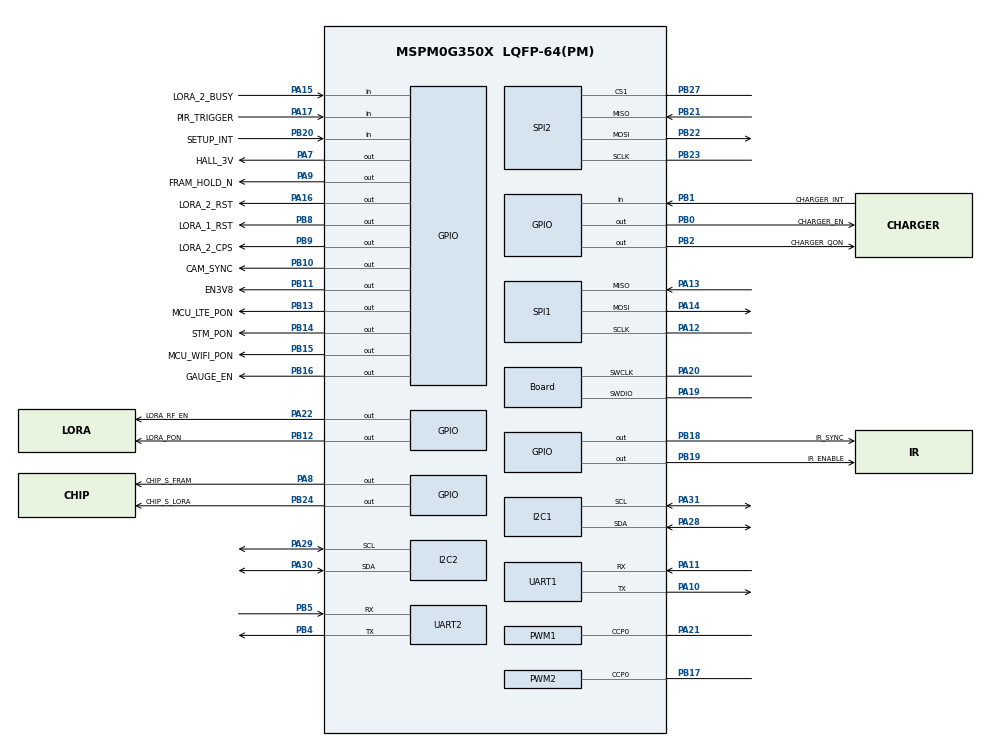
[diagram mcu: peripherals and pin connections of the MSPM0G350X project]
/**
 * @cliArgs --device "MSPM0G350X" --part "Default" --package "LQFP-64(PM)" --product "mspm0_sdk@2.09.00.01"
 * @versions {"tool":"1.25.0+4268"}
 */

/**
 * Import the modules used in this configuration.
 */
const Board  = scripting.addModule("/ti/driverlib/Board");
const GPIO   = scripting.addModule("/ti/driverlib/GPIO", {}, false);
const GPIO1  = GPIO.addInstance();
const GPIO2  = GPIO.addInstance();
const GPIO3  = GPIO.addInstance();
const I2C    = scripting.addModule("/ti/driverlib/I2C", {}, false);
const I2C1   = I2C.addInstance();
const I2C2   = I2C.addInstance();
const PWM    = scripting.addModule("/ti/driverlib/PWM", {}, false);
const PWM1   = PWM.addInstance();
const PWM2   = PWM.addInstance();
const SPI    = scripting.addModule("/ti/driverlib/SPI", {}, false);
const SPI1   = SPI.addInstance();
const SPI2   = SPI.addInstance();
const SYSCTL = scripting.addModule("/ti/driverlib/SYSCTL");
const TIMER  = scripting.addModule("/ti/driverlib/TIMER", {}, false);
const TIMER1 = TIMER.addInstance();
const UART   = scripting.addModule("/ti/driverlib/UART", {}, false);
const UART1  = UART.addInstance();
const UART2  = UART.addInstance();

/**
 * Write custom configuration values to the imported modules.
 */
Board.peripheral.swclkPin.$assign = "PA20";
Board.peripheral.swdioPin.$assign = "PA19";

GPIO1.$name                                 = "EXTERNAL_INTERRUPT";
GPIO1.associatedPins.create(4);
GPIO1.associatedPins[0].$name               = "PIR_TRIGGER";
GPIO1.associatedPins[0].direction           = "INPUT";
GPIO1.associatedPins[0].ioStructure         = "SDW";
GPIO1.associatedPins[0].assignedPin         = "17";
GPIO1.associatedPins[0].assignedPort        = "PORTA";
GPIO1.associatedPins[0].assignedPortSegment = "Upper";
GPIO1.associatedPins[0].pin.$assign         = "PA17";
GPIO1.associatedPins[1].$name               = "CHARGER_INT";
GPIO1.associatedPins[1].direction           = "INPUT";
GPIO1.associatedPins[1].assignedPin         = "any";
GPIO1.associatedPins[1].ioStructure         = "SD";
GPIO1.associatedPins[1].interruptEn         = true;
GPIO1.associatedPins[1].polarity            = "RISE_FALL";
GPIO1.associatedPins[1].pin.$assign         = "PB1";
GPIO1.associatedPins[2].$name               = "LORA_2_BUSY";
GPIO1.associatedPins[2].direction           = "INPUT";
GPIO1.associatedPins[2].ioStructure         = "SD";
GPIO1.associatedPins[2].pin.$assign         = "PA15";
GPIO1.associatedPins[3].$name               = "SETUP_INT";
GPIO1.associatedPins[3].direction           = "INPUT";
GPIO1.associatedPins[3].assignedPort        = "PORTB";
GPIO1.associatedPins[3].assignedPin         = "any";
GPIO1.associatedPins[3].pin.$assign         = "PB20";

GPIO2.$name                          = "DIGITAL_OUTPUT_PORTB";
GPIO2.port                           = "PORTB";
GPIO2.associatedPins.create(14);
GPIO2.associatedPins[0].$name        = "CHARGER_EN";
GPIO2.associatedPins[0].ioStructure  = "SD";
GPIO2.associatedPins[0].assignedPin  = "0";
GPIO2.associatedPins[0].initialValue = "SET";
GPIO2.associatedPins[0].pin.$assign  = "PB0";
GPIO2.associatedPins[1].$name        = "CHARGER_QON";
GPIO2.associatedPins[1].ioStructure  = "SD";
GPIO2.associatedPins[1].assignedPin  = "2";
GPIO2.associatedPins[1].initialValue = "SET";
GPIO2.associatedPins[1].pin.$assign  = "PB2";
GPIO2.associatedPins[2].$name        = "LORA_1_RST";
GPIO2.associatedPins[2].ioStructure  = "SD";
GPIO2.associatedPins[2].assignedPin  = "8";
GPIO2.associatedPins[2].pin.$assign  = "PB8";
GPIO2.associatedPins[3].assignedPin  = "11";
GPIO2.associatedPins[3].ioStructure  = "SD";
GPIO2.associatedPins[3].$name        = "EN3V8";
GPIO2.associatedPins[3].pin.$assign  = "PB11";
GPIO2.associatedPins[4].$name        = "LORA_PON";
GPIO2.associatedPins[4].ioStructure  = "SD";
GPIO2.associatedPins[4].assignedPin  = "12";
GPIO2.associatedPins[4].pin.$assign  = "PB12";
GPIO2.associatedPins[5].$name        = "MCU_LTE_PON";
GPIO2.associatedPins[5].ioStructure  = "SD";
GPIO2.associatedPins[5].assignedPin  = "13";
GPIO2.associatedPins[5].pin.$assign  = "PB13";
GPIO2.associatedPins[6].$name        = "STM_PON";
GPIO2.associatedPins[6].ioStructure  = "SD";
GPIO2.associatedPins[6].assignedPin  = "14";
GPIO2.associatedPins[6].pin.$assign  = "PB14";
GPIO2.associatedPins[7].ioStructure  = "SD";
GPIO2.associatedPins[7].assignedPin  = "15";
GPIO2.associatedPins[7].$name        = "MCU_WIFI_PON";
GPIO2.associatedPins[7].pin.$assign  = "PB15";
GPIO2.associatedPins[8].assignedPin  = "18";
GPIO2.associatedPins[8].ioStructure  = "SD";
GPIO2.associatedPins[8].$name        = "IR_SYNC";
GPIO2.associatedPins[8].pin.$assign  = "PB18";
GPIO2.associatedPins[9].$name        = "IR_ENABLE";
GPIO2.associatedPins[9].ioStructure  = "SD";
GPIO2.associatedPins[9].assignedPin  = "19";
GPIO2.associatedPins[9].pin.$assign  = "PB19";
GPIO2.associatedPins[10].$name       = "CAM_SYNC";
GPIO2.associatedPins[10].ioStructure = "SD";
GPIO2.associatedPins[10].assignedPin = "10";
GPIO2.associatedPins[10].pin.$assign = "PB10";
GPIO2.associatedPins[11].$name       = "GAUGE_EN";
GPIO2.associatedPins[11].pin.$assign = "PB16";
GPIO2.associatedPins[12].$name       = "LORA_2_CPS";
GPIO2.associatedPins[12].pin.$assign = "PB9";
GPIO2.associatedPins[13].$name       = "CHIP_S_LORA";
GPIO2.associatedPins[13].pin.$assign = "PB24";

GPIO3.$name                          = "DIGITAL_OUTPUT_PORTA";
GPIO3.port                           = "PORTA";
GPIO3.associatedPins.create(5);
GPIO3.associatedPins[0].$name        = "LORA_RF_EN";
GPIO3.associatedPins[0].ioStructure  = "SD";
GPIO3.associatedPins[0].assignedPin  = "22";
GPIO3.associatedPins[0].pin.$assign  = "PA22";
GPIO3.associatedPins[1].$name        = "FRAM_HOLD_N";
GPIO3.associatedPins[1].assignedPin  = "9";
GPIO3.associatedPins[1].ioStructure  = "HS";
GPIO3.associatedPins[1].initialValue = "SET";
GPIO3.associatedPins[1].pin.$assign  = "PA9";
GPIO3.associatedPins[2].$name        = "LORA_2_RST";
GPIO3.associatedPins[2].pin.$assign  = "PA16";
GPIO3.associatedPins[3].$name        = "HALL_3V";
GPIO3.associatedPins[3].pin.$assign  = "PA7";
GPIO3.associatedPins[4].$name        = "CHIP_S_FRAM";
GPIO3.associatedPins[4].initialValue = "SET";
GPIO3.associatedPins[4].pin.$assign  = "PA8";

I2C1.$name                         = "I2C_0";
I2C1.basicEnableController         = true;
I2C1.intController                 = ["ARBITRATION_LOST","NACK","RXFIFO_TRIGGER","RX_DONE","TXFIFO_TRIGGER","TX_DONE"];
I2C1.peripheral.$assign            = "I2C0";
I2C1.peripheral.sdaPin.$assign     = "PA28";
I2C1.peripheral.sclPin.$assign     = "PA31";
I2C1.sdaPinConfig.$name            = "ti_driverlib_gpio_GPIOPinGeneric9";
I2C1.sdaPinConfig.internalResistor = "PULL_UP";
I2C1.sdaPinConfig.enableConfig     = true;
I2C1.sclPinConfig.$name            = "ti_driverlib_gpio_GPIOPinGeneric10";
I2C1.sclPinConfig.internalResistor = "PULL_UP";
I2C1.sclPinConfig.enableConfig     = true;

I2C2.$name                         = "I2C_1";
I2C2.basicEnableController         = true;
I2C2.intController                 = ["ARBITRATION_LOST","NACK","RXFIFO_TRIGGER","RX_DONE","TXFIFO_TRIGGER","TX_DONE"];
I2C2.peripheral.$assign            = "I2C1";
I2C2.peripheral.sdaPin.$assign     = "PA30";
I2C2.peripheral.sclPin.$assign     = "PA29";
I2C2.sdaPinConfig.$name            = "ti_driverlib_gpio_GPIOPinGeneric11";
I2C2.sdaPinConfig.internalResistor = "PULL_UP";
I2C2.sdaPinConfig.enableConfig     = true;
I2C2.sclPinConfig.$name            = "ti_driverlib_gpio_GPIOPinGeneric12";
I2C2.sclPinConfig.internalResistor = "PULL_UP";
I2C2.sclPinConfig.enableConfig     = true;

PWM1.ccIndex                            = [0];
PWM1.clockDivider                       = 8;
PWM1.timerCount                         = 100;
PWM1.$name                              = "VOLTAGE_CONTROL";
PWM1.PWM_CHANNEL_0.$name                = "ti_driverlib_pwm_PWMTimerCC0";
PWM1.PWM_CHANNEL_0.ccValue              = 99;
PWM1.ccp0PinConfig.direction            = scripting.forceWrite("OUTPUT");
PWM1.ccp0PinConfig.hideOutputInversion  = scripting.forceWrite(false);
PWM1.ccp0PinConfig.onlyInternalResistor = scripting.forceWrite(false);
PWM1.ccp0PinConfig.passedPeripheralType = scripting.forceWrite("Digital");
PWM1.ccp0PinConfig.$name                = "ti_driverlib_gpio_GPIOPinGeneric3";
PWM1.ccp0PinConfig.internalResistor     = "PULL_DOWN";
PWM1.ccp0PinConfig.enableConfig         = true;
PWM1.peripheral.$assign                 = "TIMA0";
PWM1.peripheral.ccp0Pin.$assign         = "PA21";

PWM2.ccIndex                            = [0];
PWM2.clockDivider                       = 8;
PWM2.timerCount                         = 100;
PWM2.$name                              = "CURRENT_CONTROL";
PWM2.PWM_CHANNEL_0.$name                = "ti_driverlib_pwm_PWMTimerCC1";
PWM2.PWM_CHANNEL_0.ccValue              = 99;
PWM2.ccp0PinConfig.direction            = scripting.forceWrite("OUTPUT");
PWM2.ccp0PinConfig.hideOutputInversion  = scripting.forceWrite(false);
PWM2.ccp0PinConfig.onlyInternalResistor = scripting.forceWrite(false);
PWM2.ccp0PinConfig.passedPeripheralType = scripting.forceWrite("Digital");
PWM2.ccp0PinConfig.$name                = "ti_driverlib_gpio_GPIOPinGeneric4";
PWM2.ccp0PinConfig.enableConfig         = true;
PWM2.ccp0PinConfig.internalResistor     = "PULL_DOWN";
PWM2.peripheral.$assign                 = "TIMA1";
PWM2.peripheral.ccp0Pin.$assign         = "PB17";

SPI1.$name                                 = "SPI_0";
SPI1.targetBitRate                         = 500000;
SPI1.rxFifoThreshold                       = "DL_SPI_RX_FIFO_LEVEL_ONE_FRAME";
SPI1.txFifoThreshold                       = "DL_SPI_TX_FIFO_LEVEL_EMPTY";
SPI1.enabledDMAEvent1Triggers              = "DL_SPI_DMA_INTERRUPT_RX";
SPI1.enabledDMAEvent2Triggers              = "DL_SPI_DMA_INTERRUPT_TX";
SPI1.chipSelect                            = ["1"];
SPI1.enabledInterrupts                     = ["DMA_DONE_RX","DMA_DONE_TX","IDLE","TX_EMPTY"];
SPI1.frameFormat                           = "MOTO3";
SPI1.sclkPinConfig.$name                   = "ti_driverlib_gpio_GPIOPinGeneric0";
SPI1.mosiPinConfig.$name                   = "ti_driverlib_gpio_GPIOPinGeneric1";
SPI1.misoPinConfig.$name                   = "ti_driverlib_gpio_GPIOPinGeneric2";
SPI1.DMA_CHANNEL_EVENT1.$name              = "DMA_CH3";
SPI1.DMA_CHANNEL_EVENT1.addressMode        = "f2b";
SPI1.DMA_CHANNEL_EVENT1.srcLength          = "BYTE";
SPI1.DMA_CHANNEL_EVENT1.dstLength          = "BYTE";
SPI1.DMA_CHANNEL_EVENT2.$name              = "DMA_CH2";
SPI1.DMA_CHANNEL_EVENT2.addressMode        = "b2f";
SPI1.DMA_CHANNEL_EVENT2.srcLength          = "BYTE";
SPI1.DMA_CHANNEL_EVENT2.dstLength          = "BYTE";
SPI1.DMA_CHANNEL_EVENT2.peripheral.$assign = "DMA_CH2";
SPI1.peripheral.$assign                    = "SPI0";
SPI1.peripheral.sclkPin.$assign            = "PA12";
SPI1.peripheral.mosiPin.$assign            = "PA14";
SPI1.peripheral.misoPin.$assign            = "PA13";

SPI2.$name                                 = "SPI_1";
SPI2.peripheralChipSelect                  = "1";
SPI2.rxFifoThreshold                       = "DL_SPI_RX_FIFO_LEVEL_ONE_FRAME";
SPI2.txFifoThreshold                       = "DL_SPI_TX_FIFO_LEVEL_ONE_FRAME";
SPI2.enabledInterrupts                     = ["DMA_DONE_RX","DMA_DONE_TX","TX_EMPTY"];
SPI2.enabledDMAEvent1Triggers              = "DL_SPI_DMA_INTERRUPT_RX";
SPI2.enabledDMAEvent2Triggers              = "DL_SPI_DMA_INTERRUPT_TX";
SPI2.targetBitRate                         = 500000;
SPI2.chipSelect                            = ["1"];
SPI2.sclkPinConfig.$name                   = "ti_driverlib_gpio_GPIOPinGeneric5";
SPI2.mosiPinConfig.$name                   = "ti_driverlib_gpio_GPIOPinGeneric6";
SPI2.misoPinConfig.$name                   = "ti_driverlib_gpio_GPIOPinGeneric7";
SPI2.DMA_CHANNEL_EVENT1.addressMode        = "f2b";
SPI2.DMA_CHANNEL_EVENT1.srcLength          = "BYTE";
SPI2.DMA_CHANNEL_EVENT1.dstLength          = "BYTE";
SPI2.DMA_CHANNEL_EVENT1.$name              = "DMA_CH1";
SPI2.DMA_CHANNEL_EVENT1.peripheral.$assign = "DMA_CH1";
SPI2.DMA_CHANNEL_EVENT2.dstLength          = "BYTE";
SPI2.DMA_CHANNEL_EVENT2.srcLength          = "BYTE";
SPI2.DMA_CHANNEL_EVENT2.$name              = "DMA_CH0";
SPI2.DMA_CHANNEL_EVENT2.addressMode        = "b2f";
SPI2.DMA_CHANNEL_EVENT2.peripheral.$assign = "DMA_CH0";
SPI2.peripheral.$assign                    = "SPI1";
SPI2.peripheral.sclkPin.$assign            = "PB23";
SPI2.peripheral.mosiPin.$assign            = "PB22";
SPI2.peripheral.misoPin.$assign            = "PB21";
SPI2.peripheral.cs1Pin.$assign             = "PB27";
SPI2.cs1PinConfig.$name                    = "ti_driverlib_gpio_GPIOPinGeneric8";

SYSCTL.forceDefaultClkConfig = true;
SYSCTL.VDD                   = 3;
SYSCTL.peripheral.$assign    = "SYSCTL";

TIMER1.$name              = "TIMER_0";
TIMER1.profile            = "Basic_Periodic";
TIMER1.peripheral.$assign = "TIMG6";

UART1.$name                    = "UART_0";
UART1.targetBaudRate           = 115200;
UART1.enabledInterrupts        = ["RX","TX"];
UART1.peripheral.$assign       = "UART0";
UART1.peripheral.rxPin.$assign = "PA11";
UART1.peripheral.txPin.$assign = "PA10";
UART1.txPinConfig.$name        = "ti_driverlib_gpio_GPIOPinGeneric13";
UART1.rxPinConfig.$name        = "ti_driverlib_gpio_GPIOPinGeneric14";

UART2.$name                            = "MCU_UART_1";
UART2.peripheral.$assign               = "UART1";
UART2.peripheral.rxPin.$assign         = "PB5";
UART2.peripheral.txPin.$assign         = "PB4";
UART2.txPinConfig.direction            = scripting.forceWrite("OUTPUT");
UART2.txPinConfig.hideOutputInversion  = scripting.forceWrite(false);
UART2.txPinConfig.onlyInternalResistor = scripting.forceWrite(false);
UART2.txPinConfig.passedPeripheralType = scripting.forceWrite("Digital");
UART2.txPinConfig.$name                = "ti_driverlib_gpio_GPIOPinGeneric15";
UART2.rxPinConfig.hideOutputInversion  = scripting.forceWrite(false);
UART2.rxPinConfig.onlyInternalResistor = scripting.forceWrite(false);
UART2.rxPinConfig.passedPeripheralType = scripting.forceWrite("Digital");
UART2.rxPinConfig.$name                = "ti_driverlib_gpio_GPIOPinGeneric16";

/**
 * Pinmux solution for unlocked pins/peripherals. This ensures that minor changes to the automatic solver in a future
 * version of the tool will not impact the pinmux you originally saw.  These lines can be completely deleted in order to
 * re-solve from scratch.
 */
Board.peripheral.$suggestSolution                   = "DEBUGSS";
SPI1.DMA_CHANNEL_EVENT1.peripheral.$suggestSolution = "DMA_CH3";
